# PIC32CM6408PL10048 device description
Architecture: CORTEX-M0PLUS; Family: PIC32CMPL; Series: PIC32CMPL10
Registers are 32-bit, read-write, reset 0x0 unless marked. A register's access mark holds for its fields unless they carry their own. Offsets are from the block's base; [hi:lo] are bit positions; 'fields as' and 'values as' point back to an identical list.

## SUPC — Supply Controller
Instances: SUPC 0x40001800
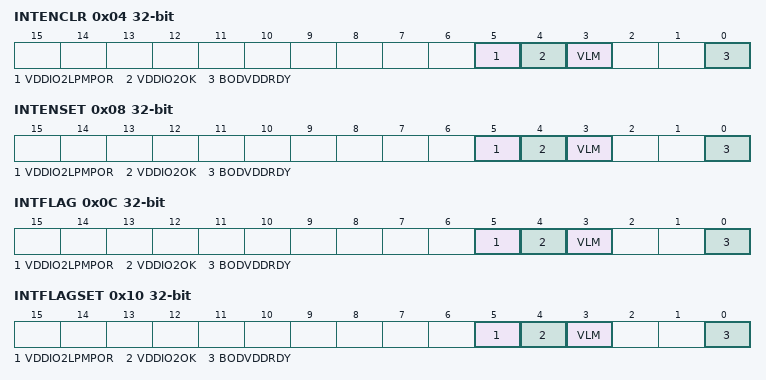
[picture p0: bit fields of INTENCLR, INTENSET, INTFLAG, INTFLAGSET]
0x04 INTENCLR (atomic clear) — Interrupt Enable Clear
  [5] VDDIO2LPMPOR — VDDIO2 Low-Power Mode POR Interrupt Enable
  [4] VDDIO2OK — VDDIO2OK Interrupt Enable
  [3] VLM — Voltage Level Monitor Interrupt Enable
  [0] BODVDDRDY — BODVDD Ready Interrupt Enable
0x08 INTENSET (atomic set) — Interrupt Enable Set
  [5] VDDIO2LPMPOR — VDDIO2 Low Power Mode POR Interrupt Enable
  [4] VDDIO2OK — VDDIO2 OK Interrupt Enable
  [3] VLM — Voltage Level Monitor Interrupt Enable
  [0] BODVDDRDY — BODVDD Ready Interrupt Enable
0x0C INTFLAG reset not defined (atomic clear) — Interrupt Flag Status and Clear
  [5] VDDIO2LPMPOR — VDDIO2 Low Power Mode POR
  [4] VDDIO2OK
  [3] VLM — Voltage Level Monitor
  [0] BODVDDRDY — BODVDD Ready
0x10 INTFLAGSET (atomic clear) — Interrupt Flag Software Set
  fields as INTFLAG
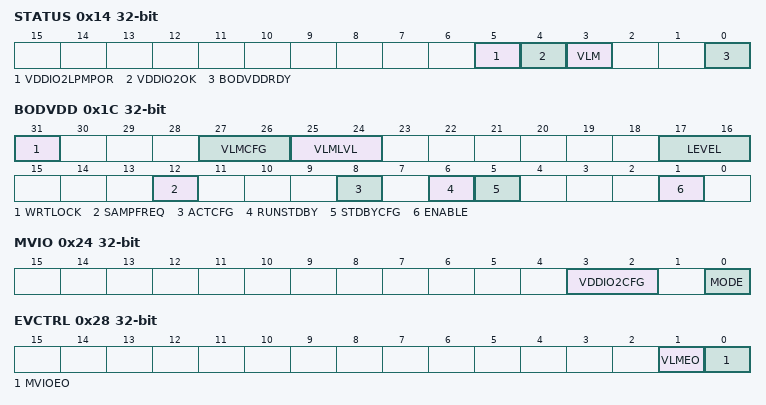
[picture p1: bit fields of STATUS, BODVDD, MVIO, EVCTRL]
0x14 STATUS ro reset not defined
  fields as INTFLAG
0x1C BODVDD — VDD Brown-Out Detector Control
  [31] WRTLOCK — Write Lock
  [27:26] VLMCFG — Voltage Level Monitor Interrupt Configuration
    0=FALLING (VDD falls below the VLM threshold); 1=RISING (VDD rises above the VLM threshold); 2=BOTH (VDD crosses the VLM threshold)
  [25:24] VLMLVL — Voltage Level Monitor Level
    0=OFF (VLM is disabled); 1=5ABOVE (The VLM threshold is 5% above the BOD threshold); 2=15ABOVE (The VLM threshold is 15% above the BOD threshold); 3=25ABOVE (The VLM threshold is 25% above the BOD threshold)
  [17:16] LEVEL — BOD Level
    0=BODLEVEL0 (1.90V); 1=BODLEVEL1 (2.45V); 2=BODLEVEL2 (2.70V); 3=BODLEVEL3 (2.85V)
  [12] SAMPFREQ — Sampling Frequency
    0=128HZ (128 Hz Sampling Frequency); 1=32HZ (32 Hz Sampling Frequency)
  [8] ACTCFG — BOD Configuration in Active Mode
    0=CONT (Continuous Mode); 1=SAMP (Sampling Mode)
  [6] RUNSTDBY — Run in Standby
  [5] STDBYCFG — BOD Configuration in Standby Sleep Mode
    0=CONT (Continuous Mode); 1=SAMP (Sampling Mode)
  [1] ENABLE
0x20 VREG — Voltage Regulator Control
  [6] RUNSTDBY — Run in Standby
0x24 MVIO — MVIO Control
  [3:2] VDDIO2CFG — VDDIO2 Configuration
    0=NORMAL (VDDIO2 with voltage protection enabled); 1=LOWPOWER (VDDIO2 with voltage protection disabled); 2=VDDIO2OFF (VDDIO2 domain is disabled. I/O pins are not available.)
  [0] MODE — Operation Mode
    0=DUAL (MVIO operating in dual supply mode); 1=SINGLE (MVIO operating in Single supply mode)
0x28 EVCTRL — Event Control
  [1] VLMEO — VLM Event Output Enable
  [0] MVIOEO — MVIO Event Output Enable
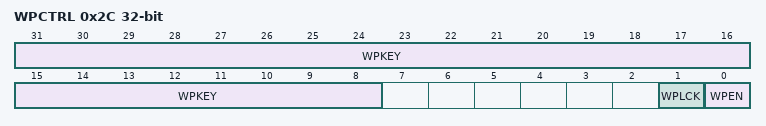
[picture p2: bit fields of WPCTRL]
0x2C WPCTRL — Write Protection Control
  [31:8] WPKEY — Write Protection Key
    0x535550=KEY (Allows writes to the WPCTRL register)
  [1] WPLCK — Write Protection Lock
  [0] WPEN — Write Protection Enable

## SYSCTRL — System Controller
Instances: SYSCTRL 0x42002C00
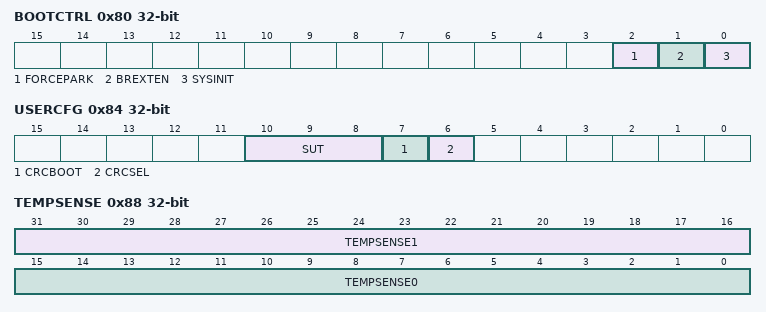
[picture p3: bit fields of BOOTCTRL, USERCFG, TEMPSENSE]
0x80 BOOTCTRL — Boot Control
  [2] FORCEPARK — Force Park Mode Entry
  [1] BREXTEN — BREXT Enable
  [0] SYSINIT — System Initialization Ongoing
0x84 USERCFG — User Configuration
  [10:8] SUT — Start-up Time
    0=0MS; 1=1MS; 2=2MS; 3=4MS; 4=8MS; 5=16MS; 6=32MS; 7=64MS
  [7] CRCBOOT
  [6] CRCSEL — CRC Polynomial Selection
    0=CRC16 (CRC-16-CCITT); 1=CRC32 (CRC-32 (IEEE 802.3))
0x88 TEMPSENSE ro reset not defined — Temperature Sensor Calibration
  [31:16] TEMPSENSE1 — Temperature Sensor Calibration Offset
  [15:0] TEMPSENSE0 — Temperature Sensor Calibration Slope

## SysTick — System timer
Instances: SysTick 0xE000E010
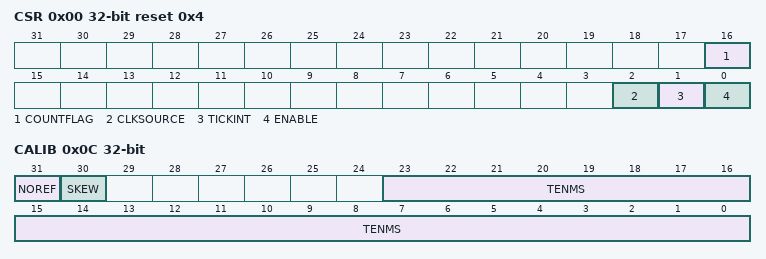
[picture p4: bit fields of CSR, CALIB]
0x00 CSR reset 0x4 — SysTick Control and Status Register
  [16] COUNTFLAG — Timer counted to 0 since last read of register
  [2] CLKSOURCE — Clock Source 0=external, 1=processor
    0=External clock; 1=Processor clock
  [1] TICKINT — SysTick Exception Request Enable
    0=Counting down to 0 does not assert the SysTick exception request; 1=Counting down to 0 asserts the SysTick exception request
  [0] ENABLE — SysTick Counter Enable
    0=Counter disabled; 1=Counter enabled
0x04 RVR reset not defined — SysTick Reload Value Register
  [23:0] RELOAD — Value to load into the SysTick Current Value Register when the counter reaches 0
0x08 CVR reset not defined — SysTick Current Value Register
  [23:0] CURRENT — Current value at the time the register is accessed
0x0C CALIB ro — SysTick Calibration Value Register
  [31] NOREF — No Separate Reference Clock
    0=The reference clock is provided; 1=The reference clock is not provided
  [30] SKEW — TENMS is rounded from non-integer ratio
    0=10ms calibration value is exact; 1=10ms calibration value is inexact, because of the clock frequency
  [23:0] TENMS — Reload value to use for 10ms timing
